VERSION ""

NS_ :

BS_:

BU_: XXX

BO_ 129 UNKNOWN_129: 4 XXX
BO_ 533 UNKNOWN_533: 8 XXX
BO_ 515 UNKNOWN_515: 7 XXX
BO_ 516 UNKNOWN_516: 1 XXX
BO_ 530 UNKNOWN_530: 7 XXX
BO_ 561 UNKNOWN_561: 5 XXX
BO_ 576 UNKNOWN_576: 8 XXX
BO_ 592 UNKNOWN_592: 8 XXX
BO_ 650 UNKNOWN_650: 1 XXX
BO_ 768 UNKNOWN_768: 1 XXX
BO_ 1072 UNKNOWN_1072: 7 XXX
BO_ 1200 UNKNOWN_1200: 8 XXX
BO_ 1201 UNKNOWN_1201: 8 XXX
BO_ 1584 UNKNOWN_1584: 8 XXX
BO_ 1616 UNKNOWN_1616: 1 XXX

BO_ 513 PCM: 8 XXX
    SG_ RPM : 0|12@0+ (1,0) [0|13000] "RPM" XXX

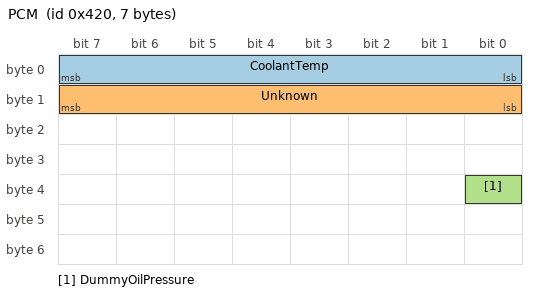
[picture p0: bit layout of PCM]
BO_ 1056 PCM: 7 Vector__XXX
    SG_ CoolantTemp : 0|8@1+ (1,0) [0|255] "degC" Vector__XXX
    SG_ Unknown : 8|8@1+ (0,0) [0|255] "" Vector__XXX
    SG_ DummyOilPressure : 32|1@1+ (0,0) [0|1] "On" Vector__XXX

VAL_ 1056 DummyOilPressure 0 "Off" 1 "On";

CM_ SG_ 513 RPM "Cannot work out conversion factor atm";
CM_ SG_ 1056 CEL_EN "Enable solid check engine lamp";
CM_ SG_ 1056 CEL_FLASH_EN "Enable blinking check engine lamp";
CM_ SG_ 1056 CLNT_EN "Enable coolant light";
CM_ SG_ 1056 BATT_EN "Enable battery light";
CM_ SG_ 1056 OIL_EN "Enable oil pressure light";
